# CY8C4247LQI_BL483 register map
File version: 0.1
PSoC 4200 BLE
Registers are 32-bit, read-write, no defined reset value unless marked. A register's access mark holds for its fields unless they carry their own. Offsets are from the block's base; lines under a group give offsets from that group; [hi:lo] are bit positions; {n}, {i} and the like mark numbered series; 'fields as' and 'values as' point back to an identical list; <NAME> marks a mode.

## Memory map
0x00000000 Opamp
0x00000000 PWM_NIR1
0x00000000 ADC_SAR — Sequencing SAR ADC
0x00000000 PWM_GREEN
0x00000000 PWM_IR_AND_RED
0x00000000 UART_DEB — Serial Communication Block

## Opamp
Base 0x00000000
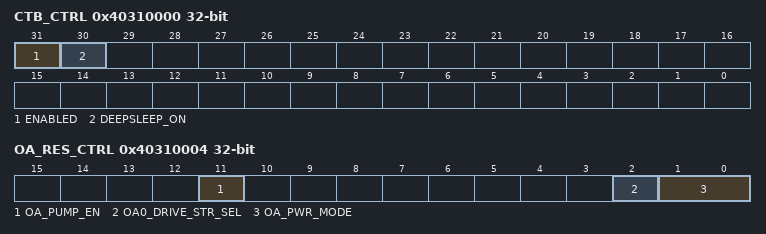
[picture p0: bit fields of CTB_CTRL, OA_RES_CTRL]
0x40310000 CTB_CTRL — Global CTB IP and power control
  [31] ENABLED — Selects component behavior in DeepSleep power mode
    0=DISABLE (CTB IP disabled (put analog in power down, open all switches)); 1=ENABLE (CTB IP enabledCTB IP enabled)
  [30] DEEPSLEEP_ON — Selects component behavior in DeepSleep power mode
    0=DISABLE (CTB IP disabled off during DeepSleep power mode); 1=ENABLE (CTB IP remains enabled during DeepSleep power mode (if ENABLED=1))
0x40310004 OA_RES_CTRL — Opamp and resistor control
  [11] OA_PUMP_EN — Selects pump
    0=DISABLE (Pump disabled); 1=ENABLE (Pump enabled)
  [2] OA0_DRIVE_STR_SEL — Opamp output strenght select
    0=Internal only; 1=Output to pin
  [1:0] OA_PWR_MODE — Selects power for opamp
    0=OFF; 1=LOW (Low power); 2=MED (Medium power); 3=HIGH (High power)
0x40310F08 OA_COMP_TRIM — Opamp Compenation Capacitor Trim
  [1:0] OA_COMP_TRIM
    1=HIGH_SPEED; 2=BALANCED; 3=HIGH_STABILITY

## PWM_NIR1
Base 0x00000000
0x400F0020 PWM_NIR1__COMPARE1 8-bit — UDB.D0 - Assigned Compare1 Value
0x400F0030 PWM_NIR1__COMPARE2 8-bit — UDB.D1 - Assigned Compare2 Value
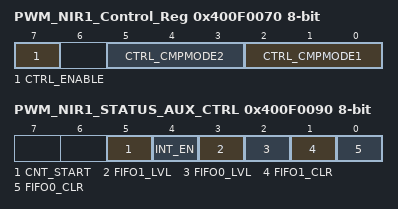
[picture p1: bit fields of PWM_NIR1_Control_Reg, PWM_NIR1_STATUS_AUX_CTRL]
0x400F0070 PWM_NIR1_Control_Reg 8-bit — UDB Control Register - Assigned Control Register Value
  [7] CTRL_ENABLE — Enable the PWM
  [5:3] CTRL_CMPMODE2 — Compare mode 2
  [2:0] CTRL_CMPMODE1 — Compare mode 1
0x400F0090 PWM_NIR1_STATUS_AUX_CTRL 8-bit — UDB Auxilliary Control Register
  [5] CNT_START — FIFO0 clear
    0=E_CNT_START0 (Disable counter); 1=E_CNT_START1 (Enable counter)
  [4] INT_EN
    0=E_INT_EN0 (Interrupt disabled); 1=E_INT_EN1 (Interrupt enabled)
  [3] FIFO1_LVL — FIFO level
    0=E_FIFO_LVL_0 (FIFO LVL: input mode: FIFO not full; output mode: FIFO not empty); 1=E_FIFO_LVL_1 (FIFO LVL: input mode: FIFO at least 1/2 empty; output mode: FIFO at least 1/2 full)
  [2] FIFO0_LVL — FIFO level
    values as FIFO1_LVL
  [1] FIFO1_CLR — FIFO1 clear
    0=E_FIFO_CLR_0 (Normal FIFO operation); 1=E_FIFO_CLR_1 (Clear FIFO state)
  [0] FIFO0_CLR — FIFO0 clear
    values as FIFO1_CLR

## PWM_GREEN
Base 0x00000000
0x400F0022 PWM_GREEN_COMPARE_Reg_ 8-bit — UDB.D0 - Assigned Compare Value
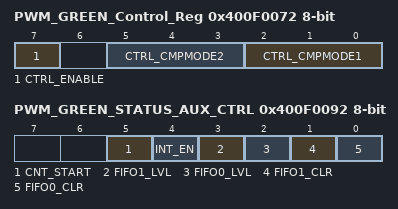
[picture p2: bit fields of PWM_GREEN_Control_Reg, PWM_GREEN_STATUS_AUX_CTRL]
0x400F0072 PWM_GREEN_Control_Reg 8-bit — UDB Control Register - Assigned Control Register Value
  [7] CTRL_ENABLE — Enable the PWM
  [5:3] CTRL_CMPMODE2 — Compare mode 2
  [2:0] CTRL_CMPMODE1 — Compare mode 1
0x400F0092 PWM_GREEN_STATUS_AUX_CTRL 8-bit — UDB Auxilliary Control Register
  [5] CNT_START — FIFO0 clear
    0=E_CNT_START0 (Disable counter); 1=E_CNT_START1 (Enable counter)
  [4] INT_EN
    0=E_INT_EN0 (Interrupt disabled); 1=E_INT_EN1 (Interrupt enabled)
  [3] FIFO1_LVL — FIFO level
    0=E_FIFO_LVL_0 (FIFO LVL: input mode: FIFO not full; output mode: FIFO not empty); 1=E_FIFO_LVL_1 (FIFO LVL: input mode: FIFO at least 1/2 empty; output mode: FIFO at least 1/2 full)
  [2] FIFO0_LVL — FIFO level
    values as FIFO1_LVL
  [1] FIFO1_CLR — FIFO1 clear
    0=E_FIFO_CLR_0 (Normal FIFO operation); 1=E_FIFO_CLR_1 (Clear FIFO state)
  [0] FIFO0_CLR — FIFO0 clear
    values as FIFO1_CLR

## PWM_IR_AND_RED
Base 0x00000000
0x400F0021 PWM_IR_AND_RED__COMPARE1 8-bit — UDB.D0 - Assigned Compare1 Value
0x400F0031 PWM_IR_AND_RED__COMPARE2 8-bit — UDB.D1 - Assigned Compare2 Value
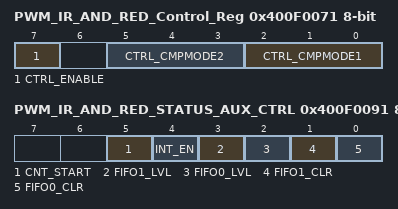
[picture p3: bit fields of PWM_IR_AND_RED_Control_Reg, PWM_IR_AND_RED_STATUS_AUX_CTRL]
0x400F0071 PWM_IR_AND_RED_Control_Reg 8-bit — UDB Control Register - Assigned Control Register Value
  [7] CTRL_ENABLE — Enable the PWM
  [5:3] CTRL_CMPMODE2 — Compare mode 2
  [2:0] CTRL_CMPMODE1 — Compare mode 1
0x400F0091 PWM_IR_AND_RED_STATUS_AUX_CTRL 8-bit — UDB Auxilliary Control Register
  [5] CNT_START — FIFO0 clear
    0=E_CNT_START0 (Disable counter); 1=E_CNT_START1 (Enable counter)
  [4] INT_EN
    0=E_INT_EN0 (Interrupt disabled); 1=E_INT_EN1 (Interrupt enabled)
  [3] FIFO1_LVL — FIFO level
    0=E_FIFO_LVL_0 (FIFO LVL: input mode: FIFO not full; output mode: FIFO not empty); 1=E_FIFO_LVL_1 (FIFO LVL: input mode: FIFO at least 1/2 empty; output mode: FIFO at least 1/2 full)
  [2] FIFO0_LVL — FIFO level
    values as FIFO1_LVL
  [1] FIFO1_CLR — FIFO1 clear
    0=E_FIFO_CLR_0 (Normal FIFO operation); 1=E_FIFO_CLR_1 (Clear FIFO state)
  [0] FIFO0_CLR — FIFO0 clear
    values as FIFO1_CLR
